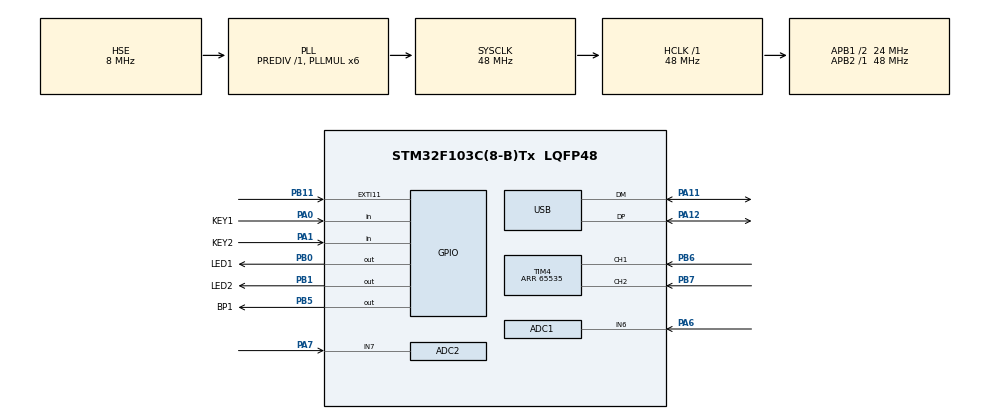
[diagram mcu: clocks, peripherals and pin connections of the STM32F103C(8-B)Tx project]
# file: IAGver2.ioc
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ADC1.Channel-1\#ChannelRegularConversion=ADC_CHANNEL_6
ADC1.Mode=ADC_DUALMODE_REGSIMULT
ADC1.NbrOfConversionFlag=1
ADC1.Rank-1\#ChannelRegularConversion=1
ADC1.SamplingTime-1\#ChannelRegularConversion=ADC_SAMPLETIME_7CYCLES_5
ADC1.master=1
ADC2.Channel-0\#ChannelRegularConversion=ADC_CHANNEL_7
ADC2.Mode=ADC_DUALMODE_REGSIMULT
ADC2.NbrOfConversionFlag=1
ADC2.Rank-0\#ChannelRegularConversion=1
ADC2.SamplingTime-0\#ChannelRegularConversion=ADC_SAMPLETIME_7CYCLES_5
Dma.ADC1.0.Direction=DMA_PERIPH_TO_MEMORY
Dma.ADC1.0.Instance=DMA1_Channel1
Dma.ADC1.0.MemDataAlignment=DMA_MDATAALIGN_WORD
Dma.ADC1.0.MemInc=DMA_MINC_ENABLE
Dma.ADC1.0.Mode=DMA_NORMAL
Dma.ADC1.0.PeriphDataAlignment=DMA_PDATAALIGN_WORD
Dma.ADC1.0.PeriphInc=DMA_PINC_DISABLE
Dma.ADC1.0.Priority=DMA_PRIORITY_MEDIUM
Dma.Request0=ADC1
Mcu.Family=STM32F1
Mcu.Name=STM32F103C(8-B)Tx
Mcu.Package=LQFP48
NVIC.ADC1_2_IRQn=true\:0\:0\:false\:false\:true\:true\:true\:true
NVIC.DMA1_Channel1_IRQn=true\:4\:0\:true\:false\:true\:false\:true\:true
NVIC.PriorityGroup=NVIC_PRIORITYGROUP_3
NVIC.TIM1_UP_IRQn=true\:3\:0\:true\:false\:true\:true\:true\:true
NVIC.TIM3_IRQn=true\:6\:0\:true\:false\:true\:true\:true\:true
NVIC.USB_HP_CAN1_TX_IRQn=true\:5\:1\:true\:false\:true\:true\:true\:true
NVIC.USB_LP_CAN1_RX0_IRQn=true\:5\:0\:true\:false\:true\:false\:true\:true
PA0-WKUP.GPIO_Label=KEY1
PA0-WKUP.Signal=GPIO_Input
PA1.GPIO_Label=KEY2
PA1.Signal=GPIO_Input
PA11.Mode=Device
PA11.Signal=USB_DM
PA12.Mode=Device
PA12.Signal=USB_DP
PA13.Mode=JTAG_5_pins
PA13.Signal=SYS_JTMS-SWDIO
PA14.Mode=JTAG_5_pins
PA14.Signal=SYS_JTCK-SWCLK
PA15.Mode=JTAG_5_pins
PA15.Signal=SYS_JTDI
PA6.Signal=ADCx_IN6
PA7.Signal=ADCx_IN7
PB0.GPIO_Label=LED1
PB0.PinState=GPIO_PIN_SET
PB0.Signal=GPIO_Output
PB1.GPIO_Label=LED2
PB1.PinState=GPIO_PIN_RESET
PB1.Signal=GPIO_Output
PB11.Signal=GPXTI11
PB3.Mode=JTAG_5_pins
PB3.Signal=SYS_JTDO-TRACESWO
PB4.Mode=JTAG_5_pins
PB4.Signal=SYS_NJTRST
PB5.GPIO_Label=BP1
PB5.Signal=GPIO_Output
PB6.GPIO_PuPd=GPIO_PULLUP
PB6.Signal=S_TIM4_CH1
PB7.GPIO_PuPd=GPIO_PULLUP
PB7.Signal=S_TIM4_CH2
PC14-OSC32_IN.Mode=LSE-External-Oscillator
PC14-OSC32_IN.Signal=RCC_OSC32_IN
PC15-OSC32_OUT.Mode=LSE-External-Oscillator
PC15-OSC32_OUT.Signal=RCC_OSC32_OUT
PD0-OSC_IN.Mode=HSE-External-Oscillator
PD0-OSC_IN.Signal=RCC_OSC_IN
PD1-OSC_OUT.Mode=HSE-External-Oscillator
PD1-OSC_OUT.Signal=RCC_OSC_OUT
ProjectManager.HeapSize=0x200
ProjectManager.StackSize=0x1600
ProjectManager.TargetToolchain=MDK-ARM V5.32
RCC.ADCPresc=RCC_ADCPCLK2_DIV4
RCC.AHBFreq_Value=48000000
RCC.APB1CLKDivider=RCC_HCLK_DIV2
RCC.APB1Freq_Value=24000000
RCC.APB1TimFreq_Value=48000000
RCC.APB2Freq_Value=48000000
RCC.APB2TimFreq_Value=48000000
RCC.EnbaleCSS=true
RCC.HCLKFreq_Value=48000000
RCC.PLLMUL=RCC_PLL_MUL6
RCC.PLLSourceVirtual=RCC_PLLSOURCE_HSE
RCC.SYSCLKFreq_VALUE=48000000
RCC.SYSCLKSource=RCC_SYSCLKSOURCE_PLLCLK
RCC.USBFreq_Value=48000000
SH.ADCx_IN6.0=ADC1_IN6,IN6
SH.ADCx_IN7.0=ADC2_IN7,IN7
SH.S_TIM4_CH1.0=TIM4_CH1,Encoder_Interface
SH.S_TIM4_CH2.0=TIM4_CH2,Encoder_Interface
TIM1.Period=1000-1
TIM1.Prescaler=480-1
TIM1.TIM_MasterOutputTrigger=TIM_TRGO_UPDATE
TIM1.TIM_MasterSlaveMode=TIM_MASTERSLAVEMODE_ENABLE
TIM3.Period=10-1
TIM3.Prescaler=10-1
TIM4.EncoderMode=TIM_ENCODERMODE_TI12
TIM4.IC1Filter=3
TIM4.IC1Polarity=TIM_ICPOLARITY_FALLING
TIM4.IC2Filter=3
TIM4.Period=65535
USB_DEVICE.CLASS_NAME_FS=CDC
USB_DEVICE.MANUFACTURER_STRING=CTP
USB_DEVICE.PID_CDC_FS=2
USB_DEVICE.PRODUCT_STRING_CDC_FS=Tensile displacement measuring instrument
USB_DEVICE.VID=61166
USB_DEVICE.VirtualMode=Cdc
USB_DEVICE.VirtualModeFS=Cdc_FS
VP_TIM1_VS_ClockSourceINT.Mode=Internal
VP_TIM3_VS_ClockSourceITR.Mode=TriggerSource_ITR0
VP_TIM3_VS_ControllerModeClock.Mode=Clock Mode
VP_USB_DEVICE_VS_USB_DEVICE_CDC_FS.Mode=CDC_FS
board=custom

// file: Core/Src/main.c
/* USER CODE BEGIN Header */
/**
  ******************************************************************************
  * @file           : main.c
  * @brief          : Main program body
  ******************************************************************************
  * @attention
  *
  * Copyright (c) 2024 STMicroelectronics.
  * All rights reserved.
  *
  * This software is licensed under terms that can be found in the LICENSE file
  * in the root directory of this software component.
  * If no LICENSE file comes with this software, it is provided AS-IS.
  *
  ******************************************************************************
  */
/* USER CODE END Header */
#include "main.h"
#include "adc.h"
#include "dma.h"
#include "tim.h"
#include "usb_device.h"
#include "gpio.h"

/* USER CODE BEGIN PV */
uint8_t cache_data_index;
uint32_t cache_adc_data[CACHE_DATA_SIZE];
uint16_t cache_tim_data[CACHE_DATA_SIZE];
// uint16_t cache_tim_cycle_data[CACHE_DATA_SIZE];
/* USER CODE END PV */

void SystemClock_Config(void);

int main(void)
{

  /* MCU Configuration--------------------------------------------------------*/

  /* Reset of all peripherals, Initializes the Flash interface and the Systick. */
  HAL_Init();

  /* Configure the system clock */
  SystemClock_Config();

  /* Initialize all configured peripherals */
  MX_GPIO_Init();
  MX_DMA_Init();
  MX_USB_DEVICE_Init();
  MX_TIM1_Init();
  MX_TIM3_Init();
  MX_TIM4_Init();
  MX_ADC1_Init();
  MX_ADC2_Init();
  /* USER CODE BEGIN 2 */

	HAL_TIM_Base_Start_IT(&htim1);
  // HAL_TIM_Base_Start_IT(&htim2);
  HAL_TIM_Base_Start_IT(&htim3);
  HAL_TIM_Encoder_Start_IT(&htim4, TIM_CHANNEL_ALL);

  HAL_ADC_Start(&hadc2); // 进行Dual转换时，从机只需要启动一�?

  /* USER CODE END 2 */

  /* Infinite loop */
  while (1)
  {

  }
}

void SystemClock_Config(void)
{
  RCC_OscInitTypeDef RCC_OscInitStruct = {0};
  RCC_ClkInitTypeDef RCC_ClkInitStruct = {0};
  RCC_PeriphCLKInitTypeDef PeriphClkInit = {0};

  /** Initializes the RCC Oscillators according to the specified parameters
  * in the RCC_OscInitTypeDef structure.
  */
  RCC_OscInitStruct.OscillatorType = RCC_OSCILLATORTYPE_HSE;
  RCC_OscInitStruct.HSEState = RCC_HSE_ON;
  RCC_OscInitStruct.HSEPredivValue = RCC_HSE_PREDIV_DIV1;
  RCC_OscInitStruct.HSIState = RCC_HSI_ON;
  RCC_OscInitStruct.PLL.PLLState = RCC_PLL_ON;
  RCC_OscInitStruct.PLL.PLLSource = RCC_PLLSOURCE_HSE;
  RCC_OscInitStruct.PLL.PLLMUL = RCC_PLL_MUL6;
  if (HAL_RCC_OscConfig(&RCC_OscInitStruct) != HAL_OK)
  {
    Error_Handler();
  }

  /** Initializes the CPU, AHB and APB buses clocks
  */
  RCC_ClkInitStruct.ClockType = RCC_CLOCKTYPE_HCLK|RCC_CLOCKTYPE_SYSCLK
                              |RCC_CLOCKTYPE_PCLK1|RCC_CLOCKTYPE_PCLK2;
  RCC_ClkInitStruct.SYSCLKSource = RCC_SYSCLKSOURCE_PLLCLK;
  RCC_ClkInitStruct.AHBCLKDivider = RCC_SYSCLK_DIV1;
  RCC_ClkInitStruct.APB1CLKDivider = RCC_HCLK_DIV2;
  RCC_ClkInitStruct.APB2CLKDivider = RCC_HCLK_DIV1;

  if (HAL_RCC_ClockConfig(&RCC_ClkInitStruct, FLASH_LATENCY_1) != HAL_OK)
  {
    Error_Handler();
  }
  PeriphClkInit.PeriphClockSelection = RCC_PERIPHCLK_ADC|RCC_PERIPHCLK_USB;
  PeriphClkInit.AdcClockSelection = RCC_ADCPCLK2_DIV4;
  PeriphClkInit.UsbClockSelection = RCC_USBCLKSOURCE_PLL;
  if (HAL_RCCEx_PeriphCLKConfig(&PeriphClkInit) != HAL_OK)
  {
    Error_Handler();
  }

  /** Enables the Clock Security System
  */
  HAL_RCC_EnableCSS();
}

void Error_Handler(void)
{
  __disable_irq();
  while (1)
  {
  }
}
